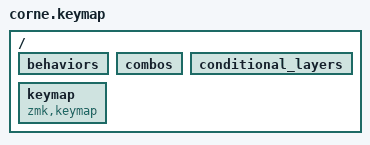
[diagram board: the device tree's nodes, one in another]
#include <behaviors.dtsi>
#include <dt-bindings/zmk/keys.h>
#include <dt-bindings/zmk/bt.h>
#include <dt-bindings/zmk/pointing.h>

// Layer IDs
#define BAZ 0
#define RIG 1
#define LEF 2
#define TRI 3
#define MOUSE 4

// Home row mods
#define HRML(k1,k2,k3,k4) &ht LSHIFT k1 &ht LALT k2 &ht LCTRL k3 &ht LGUI k4
#define HRMR(k1,k2,k3,k4) &ht RGUI k1 &ht RCTRL k2 &ht RALT k3 &ht RSHIFT k4

/ {
    behaviors {
        #include "common/layers/behaviours.dtsi"
    };

    combos {
        // Add your combos here, or create a combos.dtsi file
    };

    conditional_layers {
        #include "common/layers/conditional.dtsi"
    };

    keymap {
        compatible = "zmk,keymap";
        #include "layouts/ergol/layers/default.dtsi"
        #include "layouts/ergol/layers/right.dtsi"
        #include "layouts/ergol/layers/left.dtsi"
        #include "common/layers/tri.dtsi"
        #include "common/layers/mouse.dtsi"
    };
};
